# RockChip_RK3588 register map
Vendor: RockChip Electronics Co., Ltd.; Series: RK3588; File version: 0.1
Registers are 32-bit, read-write, no defined reset value unless marked. A register's access mark holds for its fields unless they carry their own. Offsets are from the block's base; [hi:lo] are bit positions; {n}, {i} and the like mark numbered series.

## CRU (part 4 of 6)
Base 0xFD7C0000
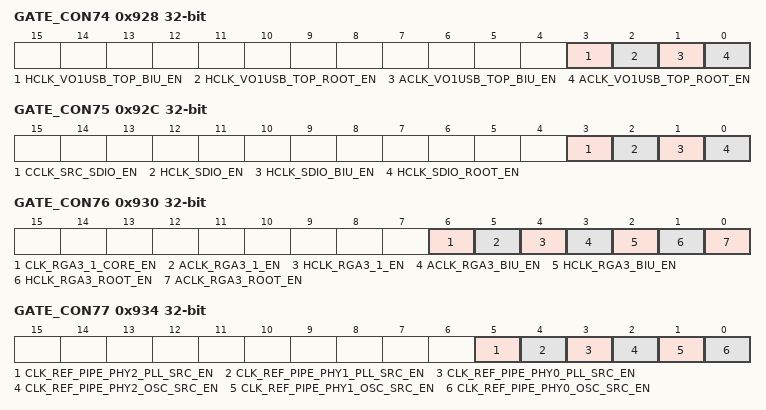
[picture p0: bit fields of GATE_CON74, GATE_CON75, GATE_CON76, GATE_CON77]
0x928 GATE_CON74 — Internal clock gate and division register 74
  [all] fields
    1=DISABLE; 0=ENABLE
  [3] HCLK_VO1USB_TOP_BIU_EN — hclk_vo1usb_top_biu clock gating control.
  [2] HCLK_VO1USB_TOP_ROOT_EN — hclk_vo1usb_top_root clock gating control.
  [1] ACLK_VO1USB_TOP_BIU_EN — aclk_vo1usb_top_biu clock gating control.
  [0] ACLK_VO1USB_TOP_ROOT_EN — aclk_vo1usb_top_root clock gating control.
0x92C GATE_CON75 — Internal clock gate and division register 75
  [all] fields
    1=DISABLE; 0=ENABLE
  [3] CCLK_SRC_SDIO_EN — cclk_src_sdio clock gating control.
  [2] HCLK_SDIO_EN — hclk_sdio clock gating control.
  [1] HCLK_SDIO_BIU_EN — hclk_sdio_biu clock gating control.
  [0] HCLK_SDIO_ROOT_EN — hclk_sdio_root clock gating control.
0x930 GATE_CON76 — Internal clock gate and division register 76
  [all] fields
    1=DISABLE; 0=ENABLE
  [6] CLK_RGA3_1_CORE_EN — clk_rga3_1_core clock gating control.
  [5] ACLK_RGA3_1_EN — aclk_rga3_1 clock gating control.
  [4] HCLK_RGA3_1_EN — hclk_rga3_1 clock gating control.
  [3] ACLK_RGA3_BIU_EN — aclk_rga3_biu clock gating control.
  [2] HCLK_RGA3_BIU_EN — hclk_rga3_biu clock gating control.
  [1] HCLK_RGA3_ROOT_EN — hclk_rga3_root clock gating control.
  [0] ACLK_RGA3_ROOT_EN — aclk_rga3_root clock gating control.
0x934 GATE_CON77 — Internal clock gate and division register 77
  [all] fields
    1=DISABLE; 0=ENABLE
  [5] CLK_REF_PIPE_PHY2_PLL_SRC_EN — clk_ref_pipe_phy2_pll_src clock gating control.
  [4] CLK_REF_PIPE_PHY1_PLL_SRC_EN — clk_ref_pipe_phy1_pll_src clock gating control.
  [3] CLK_REF_PIPE_PHY0_PLL_SRC_EN — clk_ref_pipe_phy0_pll_src clock gating control.
  [2] CLK_REF_PIPE_PHY2_OSC_SRC_EN — clk_ref_pipe_phy2_osc_src clock gating control.
  [1] CLK_REF_PIPE_PHY1_OSC_SRC_EN — clk_ref_pipe_phy1_osc_src clock gating control.
  [0] CLK_REF_PIPE_PHY0_OSC_SRC_EN — clk_ref_pipe_phy0_osc_src clock gating control.
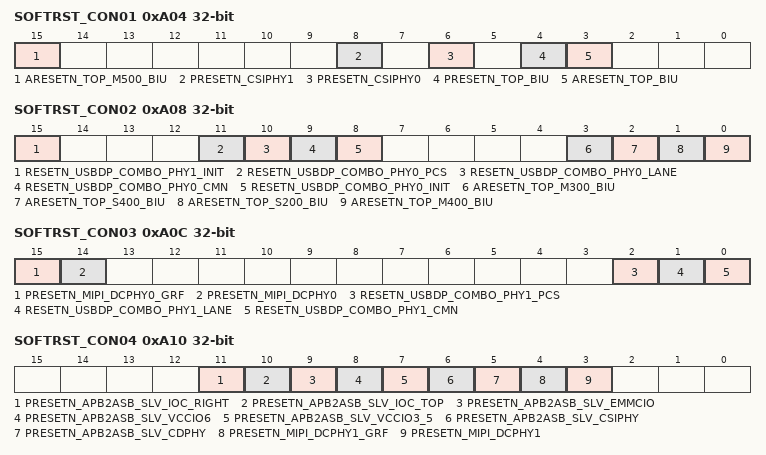
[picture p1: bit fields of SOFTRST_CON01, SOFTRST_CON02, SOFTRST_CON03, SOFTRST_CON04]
0xA04 SOFTRST_CON01 — Internal clock reset register 1
  [all] fields
    1=ASSERT
  [15] ARESETN_TOP_M500_BIU — When high, reset relative logic
  [8] PRESETN_CSIPHY1 — When high, reset relative logic
  [6] PRESETN_CSIPHY0 — When high, reset relative logic
  [4] PRESETN_TOP_BIU — When high, reset relative logic
  [3] ARESETN_TOP_BIU — When high, reset relative logic
0xA08 SOFTRST_CON02 — Internal clock reset register 2
  [all] fields
    1=ASSERT
  [15] RESETN_USBDP_COMBO_PHY1_INIT — When high, reset relative logic
  [11] RESETN_USBDP_COMBO_PHY0_PCS — When high, reset relative logic
  [10] RESETN_USBDP_COMBO_PHY0_LANE — When high, reset relative logic
  [9] RESETN_USBDP_COMBO_PHY0_CMN — When high, reset relative logic
  [8] RESETN_USBDP_COMBO_PHY0_INIT — When high, reset relative logic
  [3] ARESETN_TOP_M300_BIU — When high, reset relative logic
  [2] ARESETN_TOP_S400_BIU — When high, reset relative logic
  [1] ARESETN_TOP_S200_BIU — When high, reset relative logic
  [0] ARESETN_TOP_M400_BIU — When high, reset relative logic
0xA0C SOFTRST_CON03 — Internal clock reset register 3
  [all] fields
    1=ASSERT
  [15] PRESETN_MIPI_DCPHY0_GRF — When high, reset relative logic
  [14] PRESETN_MIPI_DCPHY0 — When high, reset relative logic
  [2] RESETN_USBDP_COMBO_PHY1_PCS — When high, reset relative logic
  [1] RESETN_USBDP_COMBO_PHY1_LANE — When high, reset relative logic
  [0] RESETN_USBDP_COMBO_PHY1_CMN — When high, reset relative logic
0xA10 SOFTRST_CON04 — Internal clock reset register 4
  [all] fields
    1=ASSERT
  [11] PRESETN_APB2ASB_SLV_IOC_RIGHT — When high, reset relative logic
  [10] PRESETN_APB2ASB_SLV_IOC_TOP — When high, reset relative logic
  [9] PRESETN_APB2ASB_SLV_EMMCIO — When high, reset relative logic
  [8] PRESETN_APB2ASB_SLV_VCCIO6 — When high, reset relative logic
  [7] PRESETN_APB2ASB_SLV_VCCIO3_5 — When high, reset relative logic
  [6] PRESETN_APB2ASB_SLV_CSIPHY — When high, reset relative logic
  [5] PRESETN_APB2ASB_SLV_CDPHY — When high, reset relative logic
  [4] PRESETN_MIPI_DCPHY1_GRF — When high, reset relative logic
  [3] PRESETN_MIPI_DCPHY1 — When high, reset relative logic
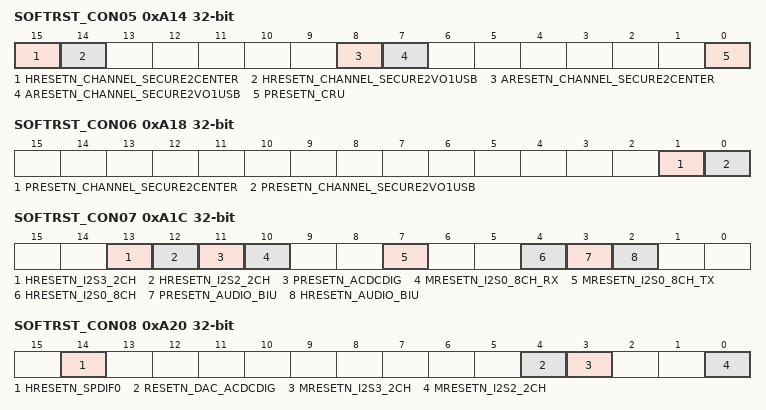
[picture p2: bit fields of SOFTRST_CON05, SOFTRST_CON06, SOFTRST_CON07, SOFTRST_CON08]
0xA14 SOFTRST_CON05 — Internal clock reset register 5
  [all] fields
    1=ASSERT
  [15] HRESETN_CHANNEL_SECURE2CENTER — When high, reset relative logic
  [14] HRESETN_CHANNEL_SECURE2VO1USB — When high, reset relative logic
  [8] ARESETN_CHANNEL_SECURE2CENTER — When high, reset relative logic
  [7] ARESETN_CHANNEL_SECURE2VO1USB — When high, reset relative logic
  [0] PRESETN_CRU — When high, reset relative logic
0xA18 SOFTRST_CON06 — Internal clock reset register 6
  [1] PRESETN_CHANNEL_SECURE2CENTER — When high, reset relative logic
    1=ASSERT
  [0] PRESETN_CHANNEL_SECURE2VO1USB — When high, reset relative logic
    1=ASSERT
0xA1C SOFTRST_CON07 — Internal clock reset register 7
  [all] fields
    1=ASSERT
  [13] HRESETN_I2S3_2CH — When high, reset relative logic
  [12] HRESETN_I2S2_2CH — When high, reset relative logic
  [11] PRESETN_ACDCDIG — When high, reset relative logic
  [10] MRESETN_I2S0_8CH_RX — When high, reset relative logic
  [7] MRESETN_I2S0_8CH_TX — When high, reset relative logic
  [4] HRESETN_I2S0_8CH — When high, reset relative logic
  [3] PRESETN_AUDIO_BIU — When high, reset relative logic
  [2] HRESETN_AUDIO_BIU — When high, reset relative logic
0xA20 SOFTRST_CON08 — Internal clock reset register 8
  [all] fields
    1=ASSERT
  [14] HRESETN_SPDIF0 — When high, reset relative logic
  [4] RESETN_DAC_ACDCDIG — When high, reset relative logic
  [3] MRESETN_I2S3_2CH — When high, reset relative logic
  [0] MRESETN_I2S2_2CH — When high, reset relative logic
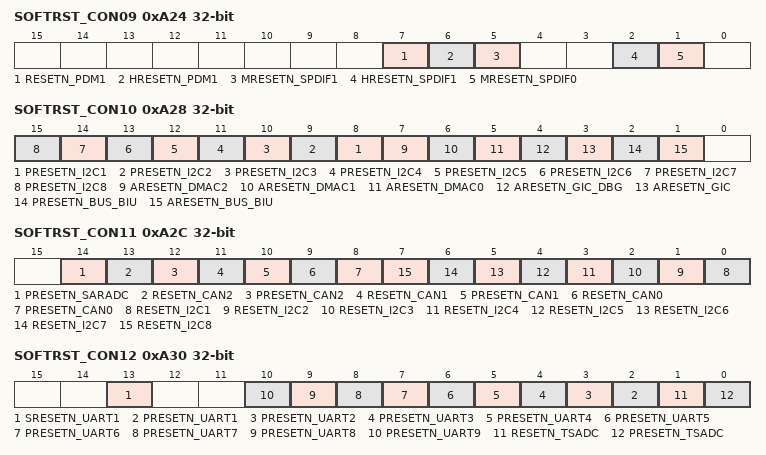
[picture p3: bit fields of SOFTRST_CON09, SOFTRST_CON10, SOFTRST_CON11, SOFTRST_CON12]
0xA24 SOFTRST_CON09 — Internal clock reset register 9
  [all] fields
    1=ASSERT
  [7] RESETN_PDM1 — When high, reset relative logic
  [6] HRESETN_PDM1 — When high, reset relative logic
  [5] MRESETN_SPDIF1 — When high, reset relative logic
  [2] HRESETN_SPDIF1 — When high, reset relative logic
  [1] MRESETN_SPDIF0 — When high, reset relative logic
0xA28 SOFTRST_CON10 — Internal clock reset register 10
  [all] fields
    1=ASSERT
  [n+7] PRESETN_I2C{n} (n=1..8) — When high, reset relative logic
  [7] ARESETN_DMAC2 — When high, reset relative logic
  [6] ARESETN_DMAC1 — When high, reset relative logic
  [5] ARESETN_DMAC0 — When high, reset relative logic
  [4] ARESETN_GIC_DBG — When high, reset relative logic
  [3] ARESETN_GIC — When high, reset relative logic
  [2] PRESETN_BUS_BIU — When high, reset relative logic
  [1] ARESETN_BUS_BIU — When high, reset relative logic
0xA2C SOFTRST_CON11 — Internal clock reset register 11
  [all] fields
    1=ASSERT
  [14] PRESETN_SARADC — When high, reset relative logic
  [13] RESETN_CAN2 — When high, reset relative logic
  [12] PRESETN_CAN2 — When high, reset relative logic
  [11] RESETN_CAN1 — When high, reset relative logic
  [10] PRESETN_CAN1 — When high, reset relative logic
  [9] RESETN_CAN0 — When high, reset relative logic
  [8] PRESETN_CAN0 — When high, reset relative logic
  [n-1] RESETN_I2C{n} (n=1..8) — When high, reset relative logic
0xA30 SOFTRST_CON12 — Internal clock reset register 12
  [all] fields
    1=ASSERT
  [13] SRESETN_UART1 — When high, reset relative logic
  [n+1] PRESETN_UART{n} (n=1..9) — When high, reset relative logic
  [1] RESETN_TSADC — When high, reset relative logic
  [0] PRESETN_TSADC — When high, reset relative logic
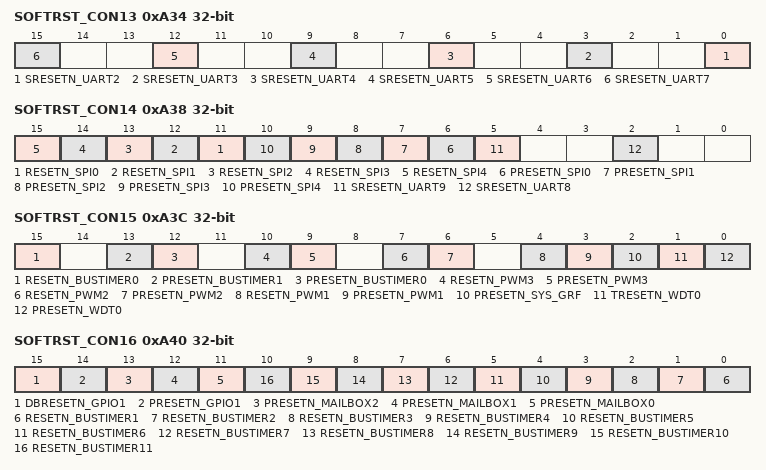
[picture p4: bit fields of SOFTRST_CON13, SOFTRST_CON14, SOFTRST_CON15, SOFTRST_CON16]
0xA34 SOFTRST_CON13 — Internal clock reset register 13
  [all] fields
    1=ASSERT
  [3n-6] SRESETN_UART{n} (n=2..7) — When high, reset relative logic
0xA38 SOFTRST_CON14 — Internal clock reset register 14
  [all] fields
    1=ASSERT
  [n+11] RESETN_SPI{n} (n=0..4) — When high, reset relative logic
  [n+6] PRESETN_SPI{n} (n=0..4) — When high, reset relative logic
  [5] SRESETN_UART9 — When high, reset relative logic
  [2] SRESETN_UART8 — When high, reset relative logic
0xA3C SOFTRST_CON15 — Internal clock reset register 15
  [all] fields
    1=ASSERT
  [15] RESETN_BUSTIMER0 — When high, reset relative logic
  [13] PRESETN_BUSTIMER1 — When high, reset relative logic
  [12] PRESETN_BUSTIMER0 — When high, reset relative logic
  [10] RESETN_PWM3 — When high, reset relative logic
  [9] PRESETN_PWM3 — When high, reset relative logic
  [7] RESETN_PWM2 — When high, reset relative logic
  [6] PRESETN_PWM2 — When high, reset relative logic
  [4] RESETN_PWM1 — When high, reset relative logic
  [3] PRESETN_PWM1 — When high, reset relative logic
  [2] PRESETN_SYS_GRF — When high, reset relative logic
  [1] TRESETN_WDT0 — When high, reset relative logic
  [0] PRESETN_WDT0 — When high, reset relative logic
0xA40 SOFTRST_CON16 — Internal clock reset register 16
  [all] fields
    1=ASSERT
  [15] DBRESETN_GPIO1 — When high, reset relative logic
  [14] PRESETN_GPIO1 — When high, reset relative logic
  [13] PRESETN_MAILBOX2 — When high, reset relative logic
  [12] PRESETN_MAILBOX1 — When high, reset relative logic
  [11] PRESETN_MAILBOX0 — When high, reset relative logic
  [n-1] RESETN_BUSTIMER{n} (n=1..11) — When high, reset relative logic
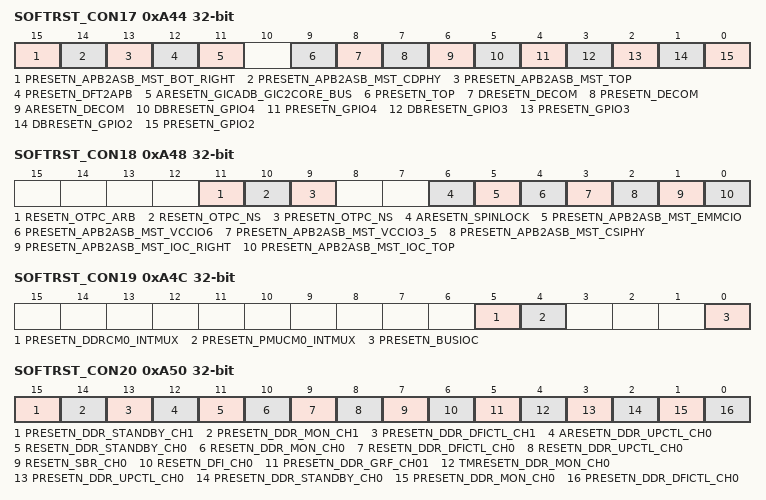
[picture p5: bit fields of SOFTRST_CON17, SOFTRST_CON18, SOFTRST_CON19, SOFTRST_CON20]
0xA44 SOFTRST_CON17 — Internal clock reset register 17
  [all] fields
    1=ASSERT
  [15] PRESETN_APB2ASB_MST_BOT_RIGHT — When high, reset relative logic
  [14] PRESETN_APB2ASB_MST_CDPHY — When high, reset relative logic
  [13] PRESETN_APB2ASB_MST_TOP — When high, reset relative logic
  [12] PRESETN_DFT2APB — When high, reset relative logic
  [11] ARESETN_GICADB_GIC2CORE_BUS — When high, reset relative logic
  [9] PRESETN_TOP — When high, reset relative logic
  [8] DRESETN_DECOM — When high, reset relative logic
  [7] PRESETN_DECOM — When high, reset relative logic
  [6] ARESETN_DECOM — When high, reset relative logic
  [5] DBRESETN_GPIO4 — When high, reset relative logic
  [4] PRESETN_GPIO4 — When high, reset relative logic
  [3] DBRESETN_GPIO3 — When high, reset relative logic
  [2] PRESETN_GPIO3 — When high, reset relative logic
  [1] DBRESETN_GPIO2 — When high, reset relative logic
  [0] PRESETN_GPIO2 — When high, reset relative logic
0xA48 SOFTRST_CON18 — Internal clock reset register 18
  [all] fields
    1=ASSERT
  [11] RESETN_OTPC_ARB — When high, reset relative logic
  [10] RESETN_OTPC_NS — When high, reset relative logic
  [9] PRESETN_OTPC_NS — When high, reset relative logic
  [6] ARESETN_SPINLOCK — When high, reset relative logic
  [5] PRESETN_APB2ASB_MST_EMMCIO — When high, reset relative logic
  [4] PRESETN_APB2ASB_MST_VCCIO6 — When high, reset relative logic
  [3] PRESETN_APB2ASB_MST_VCCIO3_5 — When high, reset relative logic
  [2] PRESETN_APB2ASB_MST_CSIPHY — When high, reset relative logic
  [1] PRESETN_APB2ASB_MST_IOC_RIGHT — When high, reset relative logic
  [0] PRESETN_APB2ASB_MST_IOC_TOP — When high, reset relative logic
0xA4C SOFTRST_CON19 — Internal clock reset register 19
  [all] fields
    1=ASSERT
  [5] PRESETN_DDRCM0_INTMUX — When high, reset relative logic
  [4] PRESETN_PMUCM0_INTMUX — When high, reset relative logic
  [0] PRESETN_BUSIOC — When high, reset relative logic
0xA50 SOFTRST_CON20 — Internal clock reset register 20
  [all] fields
    1=ASSERT
  [15] PRESETN_DDR_STANDBY_CH1 — When high, reset relative logic
  [14] PRESETN_DDR_MON_CH1 — When high, reset relative logic
  [13] PRESETN_DDR_DFICTL_CH1 — When high, reset relative logic
  [12] ARESETN_DDR_UPCTL_CH0 — When high, reset relative logic
  [11] RESETN_DDR_STANDBY_CH0 — When high, reset relative logic
  [10] RESETN_DDR_MON_CH0 — When high, reset relative logic
  [9] RESETN_DDR_DFICTL_CH0 — When high, reset relative logic
  [8] RESETN_DDR_UPCTL_CH0 — When high, reset relative logic
  [7] RESETN_SBR_CH0 — When high, reset relative logic
  [6] RESETN_DFI_CH0 — When high, reset relative logic
  [5] PRESETN_DDR_GRF_CH01 — ddr ch0 and ch1 grf presetn When high, reset relative logic
  [4] TMRESETN_DDR_MON_CH0 — When high, reset relative logic
  [3] PRESETN_DDR_UPCTL_CH0 — When high, reset relative logic
  [2] PRESETN_DDR_STANDBY_CH0 — When high, reset relative logic
  [1] PRESETN_DDR_MON_CH0 — When high, reset relative logic
  [0] PRESETN_DDR_DFICTL_CH0 — When high, reset relative logic
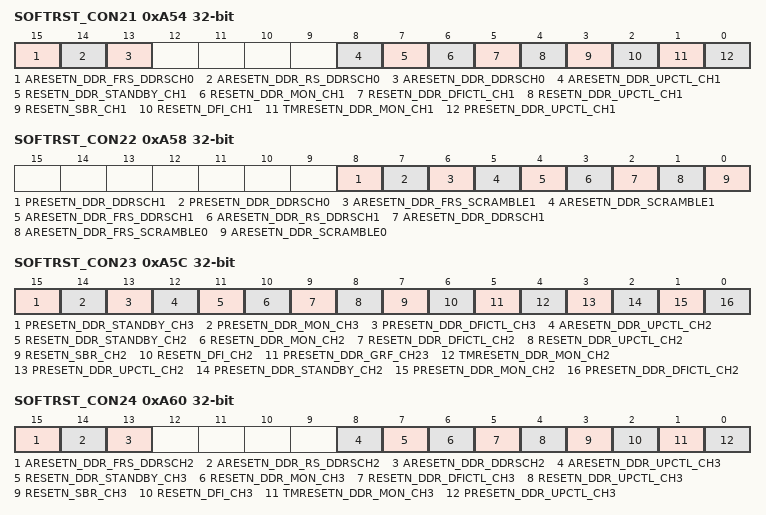
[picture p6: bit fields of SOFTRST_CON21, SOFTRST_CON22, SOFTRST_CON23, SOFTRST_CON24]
0xA54 SOFTRST_CON21 — Internal clock reset register 21
  [all] fields
    1=ASSERT
  [15] ARESETN_DDR_FRS_DDRSCH0 — When high, reset relative logic
  [14] ARESETN_DDR_RS_DDRSCH0 — When high, reset relative logic
  [13] ARESETN_DDR_DDRSCH0 — When high, reset relative logic
  [8] ARESETN_DDR_UPCTL_CH1 — When high, reset relative logic
  [7] RESETN_DDR_STANDBY_CH1 — When high, reset relative logic
  [6] RESETN_DDR_MON_CH1 — When high, reset relative logic
  [5] RESETN_DDR_DFICTL_CH1 — When high, reset relative logic
  [4] RESETN_DDR_UPCTL_CH1 — When high, reset relative logic
  [3] RESETN_SBR_CH1 — When high, reset relative logic
  [2] RESETN_DFI_CH1 — When high, reset relative logic
  [1] TMRESETN_DDR_MON_CH1 — When high, reset relative logic
  [0] PRESETN_DDR_UPCTL_CH1 — When high, reset relative logic
0xA58 SOFTRST_CON22 — Internal clock reset register 22
  [all] fields
    1=ASSERT
  [8] PRESETN_DDR_DDRSCH1 — When high, reset relative logic
  [7] PRESETN_DDR_DDRSCH0 — When high, reset relative logic
  [6] ARESETN_DDR_FRS_SCRAMBLE1 — When high, reset relative logic
  [5] ARESETN_DDR_SCRAMBLE1 — When high, reset relative logic
  [4] ARESETN_DDR_FRS_DDRSCH1 — When high, reset relative logic
  [3] ARESETN_DDR_RS_DDRSCH1 — When high, reset relative logic
  [2] ARESETN_DDR_DDRSCH1 — When high, reset relative logic
  [1] ARESETN_DDR_FRS_SCRAMBLE0 — When high, reset relative logic
  [0] ARESETN_DDR_SCRAMBLE0 — When high, reset relative logic
0xA5C SOFTRST_CON23 — Internal clock reset register 23
  [all] fields
    1=ASSERT
  [15] PRESETN_DDR_STANDBY_CH3 — When high, reset relative logic
  [14] PRESETN_DDR_MON_CH3 — When high, reset relative logic
  [13] PRESETN_DDR_DFICTL_CH3 — When high, reset relative logic
  [12] ARESETN_DDR_UPCTL_CH2 — When high, reset relative logic
  [11] RESETN_DDR_STANDBY_CH2 — When high, reset relative logic
  [10] RESETN_DDR_MON_CH2 — When high, reset relative logic
  [9] RESETN_DDR_DFICTL_CH2 — When high, reset relative logic
  [8] RESETN_DDR_UPCTL_CH2 — When high, reset relative logic
  [7] RESETN_SBR_CH2 — When high, reset relative logic
  [6] RESETN_DFI_CH2 — When high, reset relative logic
  [5] PRESETN_DDR_GRF_CH23 — ddr ch2 and ch3 grf presetn When high, reset relative logic
  [4] TMRESETN_DDR_MON_CH2 — When high, reset relative logic
  [3] PRESETN_DDR_UPCTL_CH2 — When high, reset relative logic
  [2] PRESETN_DDR_STANDBY_CH2 — When high, reset relative logic
  [1] PRESETN_DDR_MON_CH2 — When high, reset relative logic
  [0] PRESETN_DDR_DFICTL_CH2 — When high, reset relative logic
0xA60 SOFTRST_CON24 — Internal clock reset register 24
  [all] fields
    1=ASSERT
  [15] ARESETN_DDR_FRS_DDRSCH2 — When high, reset relative logic
  [14] ARESETN_DDR_RS_DDRSCH2 — When high, reset relative logic
  [13] ARESETN_DDR_DDRSCH2 — When high, reset relative logic
  [8] ARESETN_DDR_UPCTL_CH3 — When high, reset relative logic
  [7] RESETN_DDR_STANDBY_CH3 — When high, reset relative logic
  [6] RESETN_DDR_MON_CH3 — When high, reset relative logic
  [5] RESETN_DDR_DFICTL_CH3 — When high, reset relative logic
  [4] RESETN_DDR_UPCTL_CH3 — When high, reset relative logic
  [3] RESETN_SBR_CH3 — When high, reset relative logic
  [2] RESETN_DFI_CH3 — When high, reset relative logic
  [1] TMRESETN_DDR_MON_CH3 — When high, reset relative logic
  [0] PRESETN_DDR_UPCTL_CH3 — When high, reset relative logic
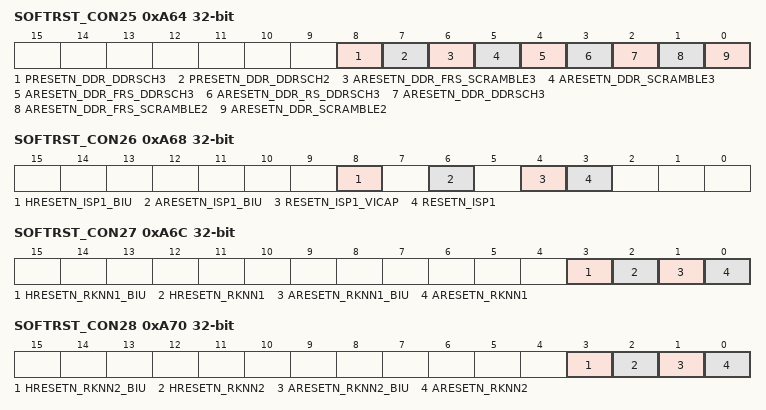
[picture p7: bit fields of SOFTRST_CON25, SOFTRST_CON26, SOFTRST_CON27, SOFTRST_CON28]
0xA64 SOFTRST_CON25 — Internal clock reset register 25
  [all] fields
    1=ASSERT
  [8] PRESETN_DDR_DDRSCH3 — When high, reset relative logic
  [7] PRESETN_DDR_DDRSCH2 — When high, reset relative logic
  [6] ARESETN_DDR_FRS_SCRAMBLE3 — When high, reset relative logic
  [5] ARESETN_DDR_SCRAMBLE3 — When high, reset relative logic
  [4] ARESETN_DDR_FRS_DDRSCH3 — When high, reset relative logic
  [3] ARESETN_DDR_RS_DDRSCH3 — When high, reset relative logic
  [2] ARESETN_DDR_DDRSCH3 — When high, reset relative logic
  [1] ARESETN_DDR_FRS_SCRAMBLE2 — When high, reset relative logic
  [0] ARESETN_DDR_SCRAMBLE2 — When high, reset relative logic
0xA68 SOFTRST_CON26 — Internal clock reset register 26
  [all] fields
    1=ASSERT
  [8] HRESETN_ISP1_BIU — When high, reset relative logic
  [6] ARESETN_ISP1_BIU — When high, reset relative logic
  [4] RESETN_ISP1_VICAP — When high, reset relative logic
  [3] RESETN_ISP1 — When high, reset relative logic
0xA6C SOFTRST_CON27 — Internal clock reset register 27
  [all] fields
    1=ASSERT
  [3] HRESETN_RKNN1_BIU — When high, reset relative logic
  [2] HRESETN_RKNN1 — When high, reset relative logic
  [1] ARESETN_RKNN1_BIU — When high, reset relative logic
  [0] ARESETN_RKNN1 — When high, reset relative logic
0xA70 SOFTRST_CON28 — Internal clock reset register 28
  [all] fields
    1=ASSERT
  [3] HRESETN_RKNN2_BIU — When high, reset relative logic
  [2] HRESETN_RKNN2 — When high, reset relative logic
  [1] ARESETN_RKNN2_BIU — When high, reset relative logic
  [0] ARESETN_RKNN2 — When high, reset relative logic
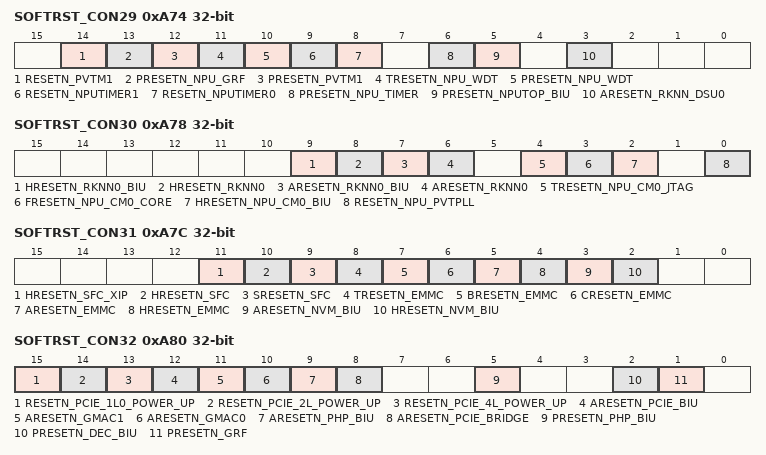
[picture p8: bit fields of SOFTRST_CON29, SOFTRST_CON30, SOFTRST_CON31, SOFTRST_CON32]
0xA74 SOFTRST_CON29 — Internal clock reset register 29
  [all] fields
    1=ASSERT
  [14] RESETN_PVTM1 — When high, reset relative logic
  [13] PRESETN_NPU_GRF — When high, reset relative logic
  [12] PRESETN_PVTM1 — When high, reset relative logic
  [11] TRESETN_NPU_WDT — When high, reset relative logic
  [10] PRESETN_NPU_WDT — When high, reset relative logic
  [9] RESETN_NPUTIMER1 — When high, reset relative logic
  [8] RESETN_NPUTIMER0 — When high, reset relative logic
  [6] PRESETN_NPU_TIMER — When high, reset relative logic
  [5] PRESETN_NPUTOP_BIU — When high, reset relative logic
  [3] ARESETN_RKNN_DSU0 — When high, reset relative logic
0xA78 SOFTRST_CON30 — Internal clock reset register 30
  [all] fields
    1=ASSERT
  [9] HRESETN_RKNN0_BIU — When high, reset relative logic
  [8] HRESETN_RKNN0 — When high, reset relative logic
  [7] ARESETN_RKNN0_BIU — When high, reset relative logic
  [6] ARESETN_RKNN0 — When high, reset relative logic
  [4] TRESETN_NPU_CM0_JTAG — When high, reset relative logic
  [3] FRESETN_NPU_CM0_CORE — When high, reset relative logic
  [2] HRESETN_NPU_CM0_BIU — When high, reset relative logic
  [0] RESETN_NPU_PVTPLL — When high, reset relative logic
0xA7C SOFTRST_CON31 — Internal clock reset register 31
  [all] fields
    1=ASSERT
  [11] HRESETN_SFC_XIP — When high, reset relative logic
  [10] HRESETN_SFC — When high, reset relative logic
  [9] SRESETN_SFC — When high, reset relative logic
  [8] TRESETN_EMMC — When high, reset relative logic
  [7] BRESETN_EMMC — When high, reset relative logic
  [6] CRESETN_EMMC — When high, reset relative logic
  [5] ARESETN_EMMC — When high, reset relative logic
  [4] HRESETN_EMMC — When high, reset relative logic
  [3] ARESETN_NVM_BIU — When high, reset relative logic
  [2] HRESETN_NVM_BIU — When high, reset relative logic
0xA80 SOFTRST_CON32 — Internal clock reset register 32
  [all] fields
    1=ASSERT
  [15] RESETN_PCIE_1L0_POWER_UP — When high, reset relative logic
  [14] RESETN_PCIE_2L_POWER_UP — When high, reset relative logic
  [13] RESETN_PCIE_4L_POWER_UP — When high, reset relative logic
  [12] ARESETN_PCIE_BIU — When high, reset relative logic
  [11] ARESETN_GMAC1 — When high, reset relative logic
  [10] ARESETN_GMAC0 — When high, reset relative logic
  [9] ARESETN_PHP_BIU — When high, reset relative logic
  [8] ARESETN_PCIE_BRIDGE — When high, reset relative logic
  [5] PRESETN_PHP_BIU — When high, reset relative logic
  [2] PRESETN_DEC_BIU — When high, reset relative logic
  [1] PRESETN_GRF — When high, reset relative logic
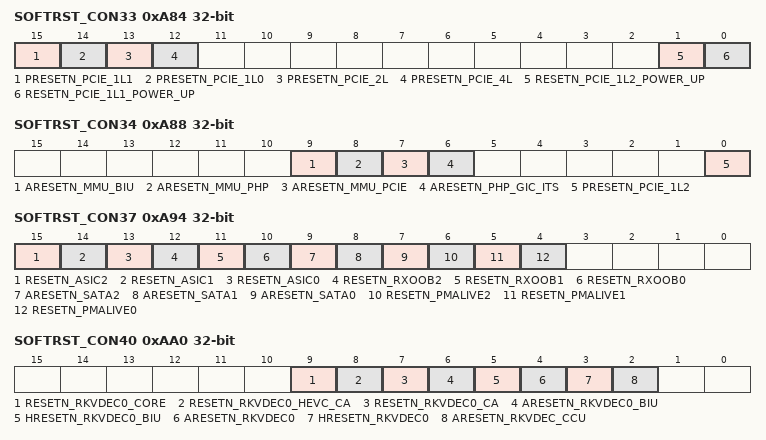
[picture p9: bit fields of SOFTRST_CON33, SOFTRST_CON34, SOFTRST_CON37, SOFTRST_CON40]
0xA84 SOFTRST_CON33 — Internal clock reset register 33
  [all] fields
    1=ASSERT
  [15] PRESETN_PCIE_1L1 — When high, reset relative logic
  [14] PRESETN_PCIE_1L0 — When high, reset relative logic
  [13] PRESETN_PCIE_2L — When high, reset relative logic
  [12] PRESETN_PCIE_4L — When high, reset relative logic
  [1] RESETN_PCIE_1L2_POWER_UP — When high, reset relative logic
  [0] RESETN_PCIE_1L1_POWER_UP — When high, reset relative logic
0xA88 SOFTRST_CON34 — Internal clock reset register 34
  [all] fields
    1=ASSERT
  [9] ARESETN_MMU_BIU — When high, reset relative logic
  [8] ARESETN_MMU_PHP — When high, reset relative logic
  [7] ARESETN_MMU_PCIE — When high, reset relative logic
  [6] ARESETN_PHP_GIC_ITS — When high, reset relative logic
  [0] PRESETN_PCIE_1L2 — When high, reset relative logic
0xA8C SOFTRST_CON35 — Internal clock reset register 35
  [7] ARESETN_USB3OTG2 — When high, reset relative logic
    1=ASSERT
0xA94 SOFTRST_CON37 — Internal clock reset register 37
  [all] fields
    1=ASSERT
  [15] RESETN_ASIC2 — When high, reset relative logic
  [14] RESETN_ASIC1 — When high, reset relative logic
  [13] RESETN_ASIC0 — When high, reset relative logic
  [12] RESETN_RXOOB2 — When high, reset relative logic
  [11] RESETN_RXOOB1 — When high, reset relative logic
  [10] RESETN_RXOOB0 — When high, reset relative logic
  [9] ARESETN_SATA2 — When high, reset relative logic
  [8] ARESETN_SATA1 — When high, reset relative logic
  [7] ARESETN_SATA0 — When high, reset relative logic
  [6] RESETN_PMALIVE2 — When high, reset relative logic
  [5] RESETN_PMALIVE1 — When high, reset relative logic
  [4] RESETN_PMALIVE0 — When high, reset relative logic
0xAA0 SOFTRST_CON40 — Internal clock reset register 40
  [all] fields
    1=ASSERT
  [9] RESETN_RKVDEC0_CORE — When high, reset relative logic
  [8] RESETN_RKVDEC0_HEVC_CA — When high, reset relative logic
  [7] RESETN_RKVDEC0_CA — When high, reset relative logic
  [6] ARESETN_RKVDEC0_BIU — When high, reset relative logic
  [5] HRESETN_RKVDEC0_BIU — When high, reset relative logic
  [4] ARESETN_RKVDEC0 — When high, reset relative logic
  [3] HRESETN_RKVDEC0 — When high, reset relative logic
  [2] ARESETN_RKVDEC_CCU — When high, reset relative logic
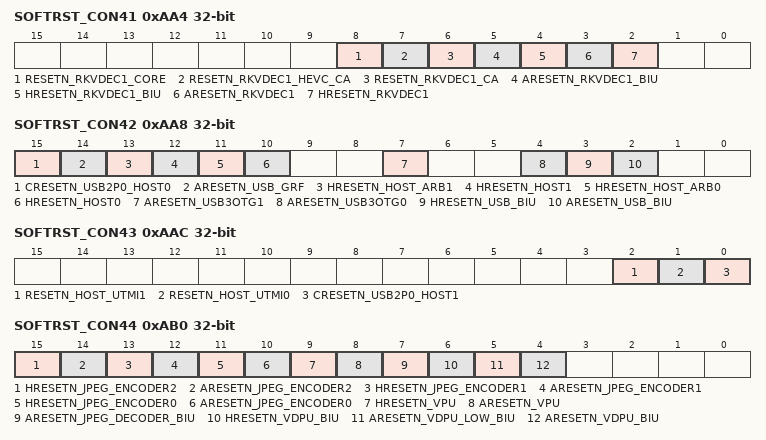
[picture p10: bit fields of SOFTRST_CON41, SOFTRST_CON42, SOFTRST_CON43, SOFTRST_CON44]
0xAA4 SOFTRST_CON41 — Internal clock reset register 41
  [all] fields
    1=ASSERT
  [8] RESETN_RKVDEC1_CORE — When high, reset relative logic
  [7] RESETN_RKVDEC1_HEVC_CA — When high, reset relative logic
  [6] RESETN_RKVDEC1_CA — When high, reset relative logic
  [5] ARESETN_RKVDEC1_BIU — When high, reset relative logic
  [4] HRESETN_RKVDEC1_BIU — When high, reset relative logic
  [3] ARESETN_RKVDEC1 — When high, reset relative logic
  [2] HRESETN_RKVDEC1 — When high, reset relative logic
0xAA8 SOFTRST_CON42 — Internal clock reset register 42
  [all] fields
    1=ASSERT
  [15] CRESETN_USB2P0_HOST0 — When high, reset relative logic
  [14] ARESETN_USB_GRF — When high, reset relative logic
  [13] HRESETN_HOST_ARB1 — When high, reset relative logic
  [12] HRESETN_HOST1 — When high, reset relative logic
  [11] HRESETN_HOST_ARB0 — When high, reset relative logic
  [10] HRESETN_HOST0 — When high, reset relative logic
  [7] ARESETN_USB3OTG1 — When high, reset relative logic
  [4] ARESETN_USB3OTG0 — When high, reset relative logic
  [3] HRESETN_USB_BIU — When high, reset relative logic
  [2] ARESETN_USB_BIU — When high, reset relative logic
0xAAC SOFTRST_CON43 — Internal clock reset register 43
  [all] fields
    1=ASSERT
  [2] RESETN_HOST_UTMI1 — When high, reset relative logic
  [1] RESETN_HOST_UTMI0 — When high, reset relative logic
  [0] CRESETN_USB2P0_HOST1 — When high, reset relative logic
0xAB0 SOFTRST_CON44 — Internal clock reset register 44
  [all] fields
    1=ASSERT
  [15] HRESETN_JPEG_ENCODER2 — When high, reset relative logic
  [14] ARESETN_JPEG_ENCODER2 — When high, reset relative logic
  [13] HRESETN_JPEG_ENCODER1 — When high, reset relative logic
  [12] ARESETN_JPEG_ENCODER1 — When high, reset relative logic
  [11] HRESETN_JPEG_ENCODER0 — When high, reset relative logic
  [10] ARESETN_JPEG_ENCODER0 — When high, reset relative logic
  [9] HRESETN_VPU — When high, reset relative logic
  [8] ARESETN_VPU — When high, reset relative logic
  [7] ARESETN_JPEG_DECODER_BIU — When high, reset relative logic
  [6] HRESETN_VDPU_BIU — When high, reset relative logic
  [5] ARESETN_VDPU_LOW_BIU — When high, reset relative logic
  [4] ARESETN_VDPU_BIU — When high, reset relative logic
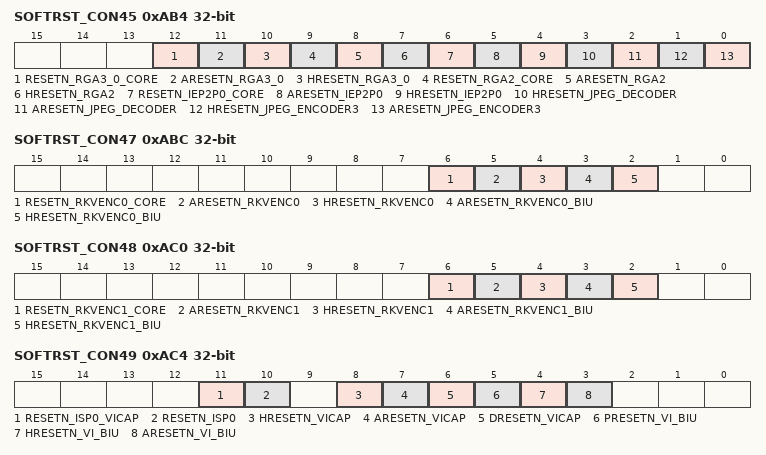
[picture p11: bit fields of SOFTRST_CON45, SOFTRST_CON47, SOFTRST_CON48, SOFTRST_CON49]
0xAB4 SOFTRST_CON45 — Internal clock reset register 45
  [all] fields
    1=ASSERT
  [12] RESETN_RGA3_0_CORE — When high, reset relative logic
  [11] ARESETN_RGA3_0 — When high, reset relative logic
  [10] HRESETN_RGA3_0 — When high, reset relative logic
  [9] RESETN_RGA2_CORE — When high, reset relative logic
  [8] ARESETN_RGA2 — When high, reset relative logic
  [7] HRESETN_RGA2 — When high, reset relative logic
  [6] RESETN_IEP2P0_CORE — When high, reset relative logic
  [5] ARESETN_IEP2P0 — When high, reset relative logic
  [4] HRESETN_IEP2P0 — When high, reset relative logic
  [3] HRESETN_JPEG_DECODER — When high, reset relative logic
  [2] ARESETN_JPEG_DECODER — When high, reset relative logic
  [1] HRESETN_JPEG_ENCODER3 — When high, reset relative logic
  [0] ARESETN_JPEG_ENCODER3 — When high, reset relative logic
0xABC SOFTRST_CON47 — Internal clock reset register 47
  [all] fields
    1=ASSERT
  [6] RESETN_RKVENC0_CORE — When high, reset relative logic
  [5] ARESETN_RKVENC0 — When high, reset relative logic
  [4] HRESETN_RKVENC0 — When high, reset relative logic
  [3] ARESETN_RKVENC0_BIU — When high, reset relative logic
  [2] HRESETN_RKVENC0_BIU — When high, reset relative logic
0xAC0 SOFTRST_CON48 — Internal clock reset register 48
  [all] fields
    1=ASSERT
  [6] RESETN_RKVENC1_CORE — When high, reset relative logic
  [5] ARESETN_RKVENC1 — When high, reset relative logic
  [4] HRESETN_RKVENC1 — When high, reset relative logic
  [3] ARESETN_RKVENC1_BIU — When high, reset relative logic
  [2] HRESETN_RKVENC1_BIU — When high, reset relative logic
0xAC4 SOFTRST_CON49 — Internal clock reset register 49
  [all] fields
    1=ASSERT
  [11] RESETN_ISP0_VICAP — When high, reset relative logic
  [10] RESETN_ISP0 — When high, reset relative logic
  [8] HRESETN_VICAP — When high, reset relative logic
  [7] ARESETN_VICAP — When high, reset relative logic
  [6] DRESETN_VICAP — When high, reset relative logic
  [5] PRESETN_VI_BIU — When high, reset relative logic
  [4] HRESETN_VI_BIU — When high, reset relative logic
  [3] ARESETN_VI_BIU — When high, reset relative logic
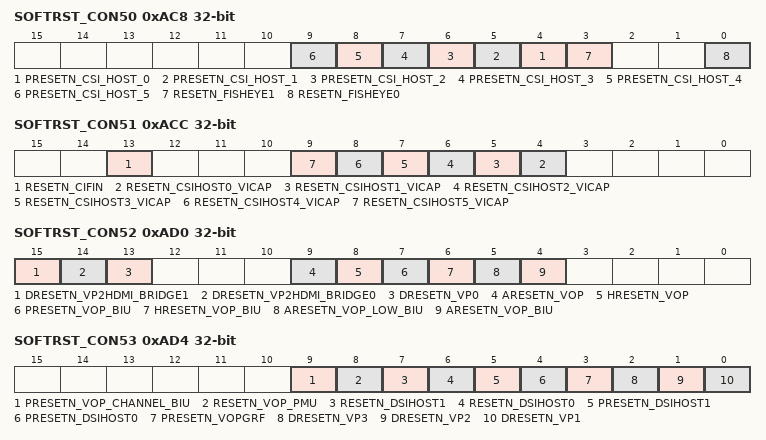
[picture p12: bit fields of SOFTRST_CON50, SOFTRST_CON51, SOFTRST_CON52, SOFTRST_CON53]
0xAC8 SOFTRST_CON50 — Internal clock reset register 50
  [all] fields
    1=ASSERT
  [n+4] PRESETN_CSI_HOST_{n} (n=0..5) — When high, reset relative logic
  [3] RESETN_FISHEYE1 — When high, reset relative logic
  [0] RESETN_FISHEYE0 — When high, reset relative logic
0xACC SOFTRST_CON51 — Internal clock reset register 51
  [all] fields
    1=ASSERT
  [13] RESETN_CIFIN — When high, reset relative logic
  [n+4] RESETN_CSIHOST{n}_VICAP (n=0..5) — When high, reset relative logic
0xAD0 SOFTRST_CON52 — Internal clock reset register 52
  [all] fields
    1=ASSERT
  [15] DRESETN_VP2HDMI_BRIDGE1 — When high, reset relative logic
  [14] DRESETN_VP2HDMI_BRIDGE0 — When high, reset relative logic
  [13] DRESETN_VP0 — When high, reset relative logic
  [9] ARESETN_VOP — When high, reset relative logic
  [8] HRESETN_VOP — When high, reset relative logic
  [7] PRESETN_VOP_BIU — When high, reset relative logic
  [6] HRESETN_VOP_BIU — When high, reset relative logic
  [5] ARESETN_VOP_LOW_BIU — When high, reset relative logic
  [4] ARESETN_VOP_BIU — When high, reset relative logic
0xAD4 SOFTRST_CON53 — Internal clock reset register 53
  [all] fields
    1=ASSERT
  [9] PRESETN_VOP_CHANNEL_BIU — When high, reset relative logic
  [8] RESETN_VOP_PMU — When high, reset relative logic
  [7] RESETN_DSIHOST1 — When high, reset relative logic
  [6] RESETN_DSIHOST0 — When high, reset relative logic
  [5] PRESETN_DSIHOST1 — When high, reset relative logic
  [4] PRESETN_DSIHOST0 — When high, reset relative logic
  [3] PRESETN_VOPGRF — When high, reset relative logic
  [2] DRESETN_VP3 — When high, reset relative logic
  [1] DRESETN_VP2 — When high, reset relative logic
  [0] DRESETN_VP1 — When high, reset relative logic
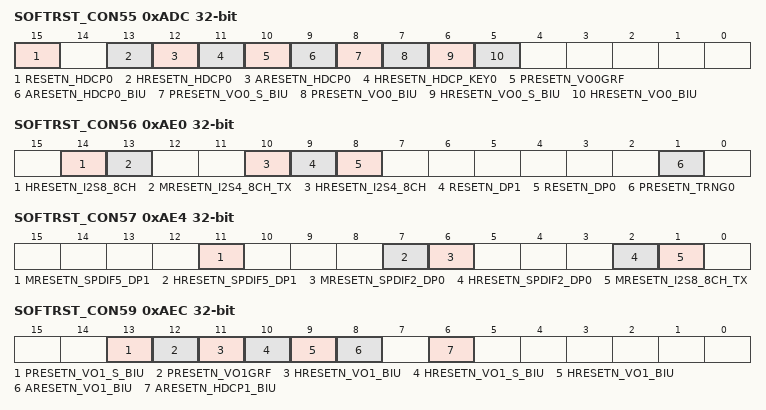
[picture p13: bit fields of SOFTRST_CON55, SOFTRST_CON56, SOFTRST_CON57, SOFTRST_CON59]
0xADC SOFTRST_CON55 — Internal clock reset register 55
  [all] fields
    1=ASSERT
  [15] RESETN_HDCP0 — When high, reset relative logic
  [13] HRESETN_HDCP0 — When high, reset relative logic
  [12] ARESETN_HDCP0 — When high, reset relative logic
  [11] HRESETN_HDCP_KEY0 — When high, reset relative logic
  [10] PRESETN_VO0GRF — When high, reset relative logic
  [9] ARESETN_HDCP0_BIU — When high, reset relative logic
  [8] PRESETN_VO0_S_BIU — When high, reset relative logic
  [7] PRESETN_VO0_BIU — When high, reset relative logic
  [6] HRESETN_VO0_S_BIU — When high, reset relative logic
  [5] HRESETN_VO0_BIU — When high, reset relative logic
0xAE0 SOFTRST_CON56 — Internal clock reset register 56
  [all] fields
    1=ASSERT
  [14] HRESETN_I2S8_8CH — When high, reset relative logic
  [13] MRESETN_I2S4_8CH_TX — When high, reset relative logic
  [10] HRESETN_I2S4_8CH — When high, reset relative logic
  [9] RESETN_DP1 — When high, reset relative logic
  [8] RESETN_DP0 — When high, reset relative logic
  [1] PRESETN_TRNG0 — When high, reset relative logic
0xAE4 SOFTRST_CON57 — Internal clock reset register 57
  [all] fields
    1=ASSERT
  [11] MRESETN_SPDIF5_DP1 — When high, reset relative logic
  [7] HRESETN_SPDIF5_DP1 — When high, reset relative logic
  [6] MRESETN_SPDIF2_DP0 — When high, reset relative logic
  [2] HRESETN_SPDIF2_DP0 — When high, reset relative logic
  [1] MRESETN_I2S8_8CH_TX — When high, reset relative logic
0xAEC SOFTRST_CON59 — Internal clock reset register 59
  [all] fields
    1=ASSERT
  [13] PRESETN_VO1_S_BIU — When high, reset relative logic
  [12] PRESETN_VO1GRF — When high, reset relative logic
  [11] HRESETN_VO1_BIU — When high, reset relative logic
  [10] HRESETN_VO1_S_BIU — When high, reset relative logic
  [9] HRESETN_VO1_BIU — When high, reset relative logic
  [8] ARESETN_VO1_BIU — When high, reset relative logic
  [6] ARESETN_HDCP1_BIU — When high, reset relative logic
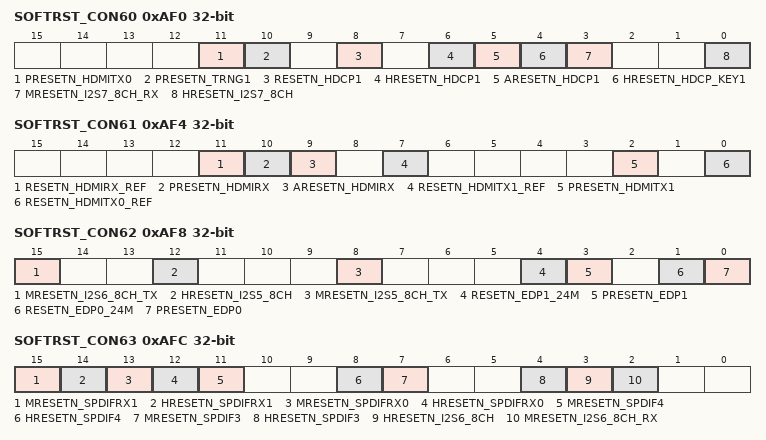
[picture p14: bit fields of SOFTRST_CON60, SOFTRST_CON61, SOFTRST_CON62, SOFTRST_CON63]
0xAF0 SOFTRST_CON60 — Internal clock reset register 60
  [all] fields
    1=ASSERT
  [11] PRESETN_HDMITX0 — When high, reset relative logic
  [10] PRESETN_TRNG1 — When high, reset relative logic
  [8] RESETN_HDCP1 — When high, reset relative logic
  [6] HRESETN_HDCP1 — When high, reset relative logic
  [5] ARESETN_HDCP1 — When high, reset relative logic
  [4] HRESETN_HDCP_KEY1 — When high, reset relative logic
  [3] MRESETN_I2S7_8CH_RX — When high, reset relative logic
  [0] HRESETN_I2S7_8CH — When high, reset relative logic
0xAF4 SOFTRST_CON61 — Internal clock reset register 61
  [all] fields
    1=ASSERT
  [11] RESETN_HDMIRX_REF — When high, reset relative logic
  [10] PRESETN_HDMIRX — When high, reset relative logic
  [9] ARESETN_HDMIRX — When high, reset relative logic
  [7] RESETN_HDMITX1_REF — When high, reset relative logic
  [2] PRESETN_HDMITX1 — When high, reset relative logic
  [0] RESETN_HDMITX0_REF — When high, reset relative logic
0xAF8 SOFTRST_CON62 — Internal clock reset register 62
  [all] fields
    1=ASSERT
  [15] MRESETN_I2S6_8CH_TX — When high, reset relative logic
  [12] HRESETN_I2S5_8CH — When high, reset relative logic
  [8] MRESETN_I2S5_8CH_TX — When high, reset relative logic
  [4] RESETN_EDP1_24M — When high, reset relative logic
  [3] PRESETN_EDP1 — When high, reset relative logic
  [1] RESETN_EDP0_24M — When high, reset relative logic
  [0] PRESETN_EDP0 — When high, reset relative logic
0xAFC SOFTRST_CON63 — Internal clock reset register 63
  [all] fields
    1=ASSERT
  [15] MRESETN_SPDIFRX1 — When high, reset relative logic
  [14] HRESETN_SPDIFRX1 — When high, reset relative logic
  [13] MRESETN_SPDIFRX0 — When high, reset relative logic
  [12] HRESETN_SPDIFRX0 — When high, reset relative logic
  [11] MRESETN_SPDIF4 — When high, reset relative logic
  [8] HRESETN_SPDIF4 — When high, reset relative logic
  [7] MRESETN_SPDIF3 — When high, reset relative logic
  [4] HRESETN_SPDIF3 — When high, reset relative logic
  [3] HRESETN_I2S6_8CH — When high, reset relative logic
  [2] MRESETN_I2S6_8CH_RX — When high, reset relative logic
0xB00 SOFTRST_CON64 — Internal clock reset register 64
  [all] fields
    1=ASSERT
  [15] RESETN_VO1_BRIDGE1 — When high, reset relative logic
  [14] RESETN_VO1_BRIDGE0 — When high, reset relative logic
  [13] RESETN_LINKSYM_HDMITXPHY1 — When high, reset relative logic
  [12] RESETN_LINKSYM_HDMITXPHY0 — When high, reset relative logic
  [1] MRESETN_SPDIFRX2 — When high, reset relative logic
  [0] HRESETN_SPDIFRX2 — When high, reset relative logic
0xB04 SOFTRST_CON65 — Internal clock reset register 65
  [all] fields
    1=ASSERT
  [8] PRESETN_S_HDMIRX — When high, reset relative logic
  [7] MRESETN_I2S10_8CH_RX — When high, reset relative logic
  [4] HRESETN_I2S10_8CH — When high, reset relative logic
  [3] MRESETN_I2S9_8CH_RX — When high, reset relative logic
  [0] HRESETN_I2S9_8CH — When high, reset relative logic
0xB08 SOFTRST_CON66 — Internal clock reset register 66
  [all] fields
    1=ASSERT
  [15] PRESETN_PVTM2 — When high, reset relative logic
  [14] PRESETN_GPU_BIU — When high, reset relative logic
  [n+9] ARESETN_M{n}_GPU_BIU (n=0..3) — When high, reset relative logic
  [8] ARESETN_S_GPU_BIU — When high, reset relative logic
  [5] SYSRESETN_GPU — When high, reset relative logic
  [4] RESETN_GPU — When high, reset relative logic
0xB0C SOFTRST_CON67 — Internal clock reset register 67
  [all] fields
    1=ASSERT
  [4] PORESETN_GPU_JTAG — When high, reset relative logic
  [3] RESETN_GPU_PVTPLL — When high, reset relative logic
  [2] PRESETN_GPU_GRF — When high, reset relative logic
  [0] RESETN_PVTM2 — When high, reset relative logic
0xB10 SOFTRST_CON68 — Internal clock reset register 68
  [all] fields
    1=ASSERT
  [5] PRESETN_AV1 — When high, reset relative logic
  [4] PRESETN_AV1_BIU — When high, reset relative logic
  [2] ARESETN_AV1 — When high, reset relative logic
  [1] ARESETN_AV1_BIU — When high, reset relative logic
0xB14 SOFTRST_CON69 — Internal clock reset register 69
  [all] fields
    1=ASSERT
  [14] FRESETN_DDR_CM0_CORE — When high, reset relative logic
  [13] HRESETN_CENTER_BIU — When high, reset relative logic
  [12] HRESETN_AHB2APB — When high, reset relative logic
  [11] ARESETN_CENTER_S400_BIU — When high, reset relative logic
  [10] ARESETN_CENTER_S200_BIU — When high, reset relative logic
  [7] ARESETN_DDR_SHAREMEM_BIU — When high, reset relative logic
  [6] ARESETN_DDR_SHAREMEM — When high, reset relative logic
  [5] ARESETN_DMA2DDR — When high, reset relative logic
  [4] ARESETN_DDR_BIU — When high, reset relative logic
0xB18 SOFTRST_CON70 — Internal clock reset register 70
  [all] fields
    1=ASSERT
  [12] PRESETN_CENTER_CHANNEL_BIU — When high, reset relative logic
  [11] PRESETN_CENTER_BIU — When high, reset relative logic
  [10] PRESETN_SHAREMEM — When high, reset relative logic
  [9] PRESETN_DMA2DDR — When high, reset relative logic
  [8] PRESETN_TIMER — When high, reset relative logic
  [7] PRESETN_WDT — When high, reset relative logic
  [6] PRESETN_AHB2APB — When high, reset relative logic
  [5] PRESETN_CENTER_GRF — When high, reset relative logic
  [3] TRESETN_DDR_CM0_JTAG — When high, reset relative logic
  [2] TRESETN_WDT_DDR — When high, reset relative logic
  [1] RESETN_DDR_TIMER1 — When high, reset relative logic
  [0] RESETN_DDR_TIMER0 — When high, reset relative logic
0xB20 SOFTRST_CON72 — Internal clock reset register 72
  [all] fields
    1=ASSERT
  [11] PRESETN_USB2PHY_U2_1_GRF0 — When high, reset relative logic
  [10] PRESETN_USB2PHY_U2_0_GRF0 — When high, reset relative logic
  [9] PRESETN_USB2PHY_U3_1_GRF0 — When high, reset relative logic
  [8] PRESETN_USB2PHY_U3_0_GRF0 — When high, reset relative logic
  [7] PRESETN_APB2ASB_SLV_BOT_RIGHT — When high, reset relative logic
  [6] PRESETN_HDPTX1 — When high, reset relative logic
  [5] PRESETN_HDPTX0 — When high, reset relative logic
  [4] PRESETN_USBDPPHY1 — When high, reset relative logic
  [3] PRESETN_USBDPGRF1 — When high, reset relative logic
  [2] PRESETN_USBDPPHY0 — When high, reset relative logic
  [1] PRESETN_USBDPGRF0 — When high, reset relative logic
0xB24 SOFTRST_CON73 — Internal clock reset register 73
  [13] RESETN_HDMIHDP1 — When high, reset relative logic
    1=ASSERT
  [12] RESETN_HDMIHDP0 — When high, reset relative logic
    1=ASSERT
0xB28 SOFTRST_CON74 — Internal clock reset register 74
  [3] HRESETN_VO1USB_TOP_BIU — When high, reset relative logic
    1=ASSERT
  [1] ARESETN_VO1USB_TOP_BIU — When high, reset relative logic
    1=ASSERT
0xB2C SOFTRST_CON75 — Internal clock reset register 75
  [all] fields
    1=ASSERT
  [3] RESETN_SDIO — When high, reset relative logic
  [2] HRESETN_SDIO — When high, reset relative logic
  [1] HRESETN_SDIO_BIU — When high, reset relative logic
0xB30 SOFTRST_CON76 — Internal clock reset register 76
  [all] fields
    1=ASSERT
  [6] RESETN_RGA3_1_CORE — When high, reset relative logic
  [5] ARESETN_RGA3_1 — When high, reset relative logic
  [4] HRESETN_RGA3_1 — When high, reset relative logic
  [3] ARESETN_RGA3_BIU — When high, reset relative logic
  [2] HRESETN_RGA3_BIU — When high, reset relative logic
0xB34 SOFTRST_CON77 — Internal clock reset register 77
  [all] fields
    1=ASSERT
  [8] RESETN_REF_PIPE_PHY2 — When high, reset relative logic
  [7] RESETN_REF_PIPE_PHY1 — When high, reset relative logic
  [6] RESETN_REF_PIPE_PHY0 — When high, reset relative logic
0xC00 GLB_CNT_TH — System control register
  [9:0] GLOBAL_RESET_COUNTER_THRESHOLD — global_reset_counter_threshold Global soft reset, wdt reset or tsadc_shut reset asserted time counter threshold. Measured in OSC clock cycles
